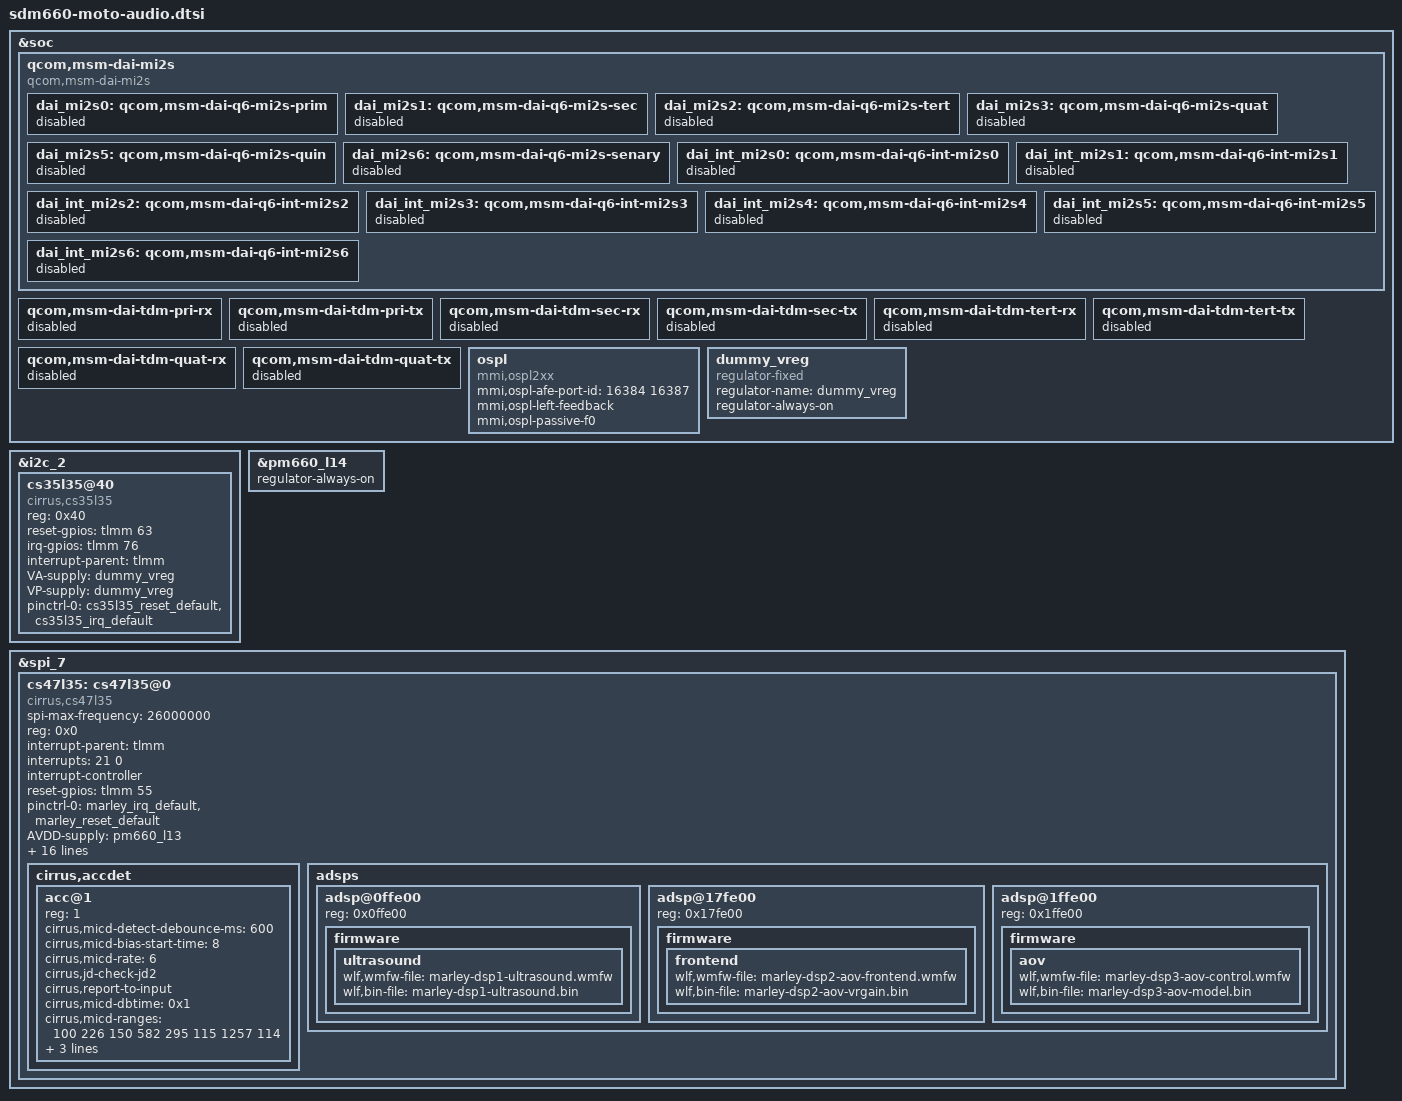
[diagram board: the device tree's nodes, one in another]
&soc {
	qcom,msm-dai-mi2s {
		compatible = "qcom,msm-dai-mi2s";
		dai_mi2s0: qcom,msm-dai-q6-mi2s-prim {
			status = "disabled";
		};

		dai_mi2s1: qcom,msm-dai-q6-mi2s-sec {
			status = "disabled";
		};

		dai_mi2s2: qcom,msm-dai-q6-mi2s-tert {
			status = "disabled";
		};

		dai_mi2s3: qcom,msm-dai-q6-mi2s-quat {
			status = "disabled";
		};

		dai_mi2s5: qcom,msm-dai-q6-mi2s-quin {
			status = "disabled";
		};

		dai_mi2s6: qcom,msm-dai-q6-mi2s-senary {
			status = "disabled";
		};

		dai_int_mi2s0: qcom,msm-dai-q6-int-mi2s0 {
			status = "disabled";
		};

		dai_int_mi2s1: qcom,msm-dai-q6-int-mi2s1 {
			status = "disabled";
		};

		dai_int_mi2s2: qcom,msm-dai-q6-int-mi2s2 {
			status = "disabled";
		};

		dai_int_mi2s3: qcom,msm-dai-q6-int-mi2s3 {
			status = "disabled";
		};

		dai_int_mi2s4: qcom,msm-dai-q6-int-mi2s4 {
			status = "disabled";
		};

		dai_int_mi2s5: qcom,msm-dai-q6-int-mi2s5 {
			status = "disabled";
		};

		dai_int_mi2s6: qcom,msm-dai-q6-int-mi2s6 {
			status = "disabled";
		};
	};

	qcom,msm-dai-tdm-pri-rx {
		status = "disabled";
	};

	qcom,msm-dai-tdm-pri-tx {
		status = "disabled";
	};

	qcom,msm-dai-tdm-sec-rx {
		status = "disabled";
	};

	qcom,msm-dai-tdm-sec-tx {
		status = "disabled";
	};

	qcom,msm-dai-tdm-tert-rx {
		status = "disabled";
	};

	qcom,msm-dai-tdm-tert-tx {
		status = "disabled";
	};

	qcom,msm-dai-tdm-quat-rx {
		status = "disabled";
	};

	qcom,msm-dai-tdm-quat-tx {
		status = "disabled";
	};

	ospl {
		compatible = "mmi,ospl2xx";
		status = "ok";
		mmi,ospl-afe-port-id = <16384 16387>;
		mmi,ospl-left-feedback;
		mmi,ospl-passive-f0;
	};

	dummy_vreg: dummy_vreg {
		compatible = "regulator-fixed";
		status = "ok";
		regulator-name = "dummy_vreg";
		regulator-always-on;
	};
	/delete-node/ qcom,wcd-dsp-mgr;
	/delete-node/ qcom,wcd-dsp-glink;
	/delete-node/ sound-9335;
	/delete-node/ sound-tavil;

};

&i2c_2 {
	status = "ok";
	cs35l35@40 {
		compatible = "cirrus,cs35l35";
		reg = <0x40>;
		reset-gpios = <&tlmm 63 0>;
		irq-gpios = <&tlmm 76 0>;
		interrupt-parent = <&tlmm>;
		VA-supply = <&dummy_vreg>;
		VP-supply = <&dummy_vreg>;

		pinctrl-names = "default";
		pinctrl-0 = <&cs35l35_reset_default &cs35l35_irq_default>;
	};
};

&pm660_l14 {
	regulator-always-on;
};

&spi_7 {
	status = "ok";
	cs47l35: cs47l35@0 {
		compatible = "cirrus,cs47l35";
		spi-max-frequency = <26000000>;
		reg = <0x0>;
		interrupt-parent = <&tlmm>;
		interrupts = <21 0>;
		interrupt-controller;
		#interrupt-cells = <2>;
		reset-gpios = <&tlmm 55 0>;
		pinctrl-names = "default";
		pinctrl-0 = <&marley_irq_default &marley_reset_default>;

		AVDD-supply = <&pm660_l13>;
		DBVDD1-supply = <&pm660_l13>;
		DBVDD2-supply = <&pm660_l13>;
		CPVDD-supply = <&pm660_l13>;
		CPVDD1-supply = <&pm660_l13>;
		CPVDD2-supply = <&pm660_l14>;
		DCVDD-supply = <&pm660_l13>;
		SPKVDD-supply = <&dummy_vreg>;

		gpio-controller;
		#gpio-cells = <2>;

		cirrus,gpio-defaults = <
			0x00002000 0x0000f000 /* AIF3TXDAT / GPIO1  */
			0x00002000 0x0000f000 /* AIF3BCLK  / GPIO2  */
			0x00000040 0x00000000 /* AIF3RXDAT / GPIO3  */
			0x00002000 0x0000f000 /* AIF3LRCLK / GPIO4  */
			0x00002000 0x0000f000 /* GPIO5 */
			0x00002000 0x0000f000 /* GPIO6 */
			0x00002000 0x0000f000 /* MIF1SDA   / GPIO7  */
			0x00002000 0x0000f000 /* AIF1RXDAT / GPIO8  */
			0x00002000 0x0000f000 /* AIF1BCLK  / GPIO9  */
			0x00002000 0x0000f000 /* AIF1TXDAT / GPIO10 */
			0x00002000 0x0000f000 /* AIF1LRCLK / GPIO11 */
			0x00002000 0x0000f000 /* AIF2TXDAT / GPIO12 */
			0x00002000 0x0000f000 /* AIF2BCLK  / GPIO13 */
			0xffffffff 0xffffffff /* AIF2RXDAT / GPIO14 */
			0xffffffff 0xffffffff /* AIF2LRCLK / GPIO15 */
			0x00002000 0x0000f000 /* MIF1SCLK  / GPIO16 */
			>;

		cirrus,micbias1 = <2600 1 1 1 1 1 1 0>;
		cirrus,micbias2 = <2600 1 1 1 1 1 1 0>;
		cirrus,micbias3 = <2600 1 1 1 1 1 1 0>;
		cirrus,micbias4 = <2600 1 1 1 1 1 1 0>;
		cirrus,inmode = <
			0 0 0 0
			0 0 0 0
		>;
		cirrus,out-mono = <0 0 0 0 0 0>;

		cirrus,accdet {
			#address-cells = <1>;
			#size-cells = <0>;

			acc@1 {
				reg = <1>;

				cirrus,micd-detect-debounce-ms = <600>;
				cirrus,micd-bias-start-time = <8>;
				cirrus,micd-rate = <6>;
				cirrus,jd-check-jd2;
				cirrus,report-to-input;
				cirrus,micd-dbtime = <0x1>;
				cirrus,micd-ranges = <
					100 226  /* HEADSETHOOK  */
					150 582  /* VOICE_ASSIST */
					295 115  /* VOLUME_UP    */
					1257 114 /* VOLUME_DOWN  */
				>;
				cirrus,micd-configs = <
					0 1 2 0 0
				>;
				cirrus,micd-clamp-mode = <0x4>;
				cirrus,gpsw = <1>;
			};
		};

		adsps {
			#address-cells = <1>;
			#size-cells = <0>;
			adsp@0ffe00 {
				reg = <0x0ffe00>;
				firmware {
					ultrasound {
						wlf,wmfw-file = "marley-dsp1-ultrasound.wmfw";
						wlf,bin-file = "marley-dsp1-ultrasound.bin";
					};
				};
			};
			adsp@17fe00 {
				reg = <0x17fe00>;
				firmware {
					frontend {
						wlf,wmfw-file = "marley-dsp2-aov-frontend.wmfw";
						wlf,bin-file = "marley-dsp2-aov-vrgain.bin";
					};
				};
			};
			adsp@1ffe00 {
				reg = <0x1ffe00>;
				firmware {
					aov {
						wlf,wmfw-file = "marley-dsp3-aov-control.wmfw";
						wlf,bin-file = "marley-dsp3-aov-model.bin";
					};
				};
			};
		};
	};
};
